# ARM_Example register map
Vendor: ARM Ltd.; Series: ARMCM3; File version: 1.2
ARM 32-bit Cortex-M3 Microcontroller based device, CPU clock up to 80MHz, etc.
CPU: CM3 r1p0, little endian, MPU, no FPU, 3 interrupt priority bits
Registers are 32-bit, read-write, reset 0x0 unless marked. A register's access mark holds for its fields unless they carry their own. Offsets are from the block's base; lines under a group give offsets from that group; [hi:lo] are bit positions; {n}, {i} and the like mark numbered series; 'fields as' and 'values as' point back to an identical list; <NAME> marks a mode.

## Memory map
0x40010000 TIMER0 size 0x100 — 32 Timer / Counter, counting up or down from different sources
0x40010100 TIMER1 size 0x100
0x40010200 TIMER2 size 0x100
0x40020000 TEST1
0x40030000 TEST2

## Interrupts
0 TIMER0
4 TIMER1
6 TIMER2

## TEST1
Base 0x40020000; register names take the prefix TEST1_
Same registers: TEST2 0x40030000 (register names take the prefix TEST1_; register names take the suffix _TEST2)
0x00 BASE1 reset 0x8001 — Timer Control Register
  [0] EN — Enable
    0=Disable (Timer is disabled and does not operate); 1=Enable (Timer is enabled and can operate)
? DIMNOINDEX{i} (i=0..3; step 0x4) reset 0x12345678 (reset mask 0x87654321)
0x04 DERIVED1 reset 0x8001 — Derived register
  fields as BASE1
0x08 DERIVED2 reset 0x8001 — Derived register
  fields as BASE1
0x10 INHERITED reset 0x12345678 (reset mask 0x87654321)
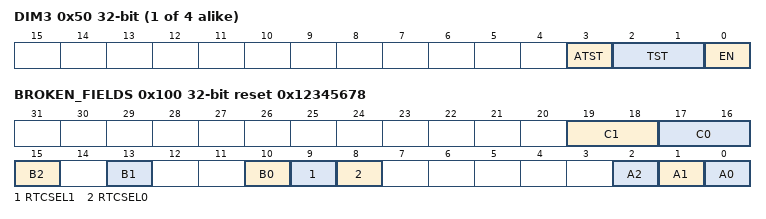
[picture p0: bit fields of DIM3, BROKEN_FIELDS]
{0x44+4i} DIM{i} (i=3..6) — test register
  [3] ATST — Another Test
  [2:1] TST — Test
  [0] EN — Enable
    values as BASE1.EN
0x100 BROKEN_FIELDS reset 0x12345678 (reset mask 0x87654321) — A register with broken field, e.g A1, A2, A3 which are supposed to only one field, name A
  [19:18] C1
  [17:16] C0
  [15] B2
  [13] B1
  [10] B0
  [9] RTCSEL1 — RTC clock source selection
  [8] RTCSEL0 — RTC clock source selection
  [2] A2
  [1] A1
  [0] A0

## Licence text in the file
ARM Limited (ARM) is supplying this software for use with Cortex-M processor based microcontroller, but can be equally used for other suitable processor architectures. This file can be freely distributed. Modifications to this file shall be clearly marked. . THIS SOFTWARE IS PROVIDED "AS IS". NO WARRANTIES, WHETHER EXPRESS, IMPLIED. OR STATUTORY, INCLUDING, BUT NOT LIMITED TO, IMPLIED WARRANTIES OF. MERCHANTABILITY AND FITNESS FOR A PARTICULAR PURPOSE APPLY TO THIS SOFTWARE. ARM SHALL NOT, IN ANY CIRCUMSTANCES, BE LIABLE FOR SPECIAL, INCIDENTAL, OR. CONSEQUENTIAL DAMAGES, FOR ANY REASON WHATSOEVER.

## Notices in the file
Copyright (C) 2012-2014 ARM Limited. All rights reserved.
Copyright (C) 2018 BayLibre
Purpose: System Viewer Description (SVD) Example (Schema Version 1.1)
This is a description of a none-existent and incomplete device
for demonstration purposes only.
Redistribution and use in source and binary forms, with or without
modification, are permitted provided that the following conditions are met:
- Redistributions of source code must retain the above copyright
notice, this list of conditions and the following disclaimer.
- Redistributions in binary form must reproduce the above copyright
notice, this list of conditions and the following disclaimer in the
documentation and/or other materials provided with the distribution.
- Neither the name of ARM nor the names of its contributors may be used
to endorse or promote products derived from this software without
specific prior written permission.
THIS SOFTWARE IS PROVIDED BY THE COPYRIGHT HOLDERS AND CONTRIBUTORS "AS IS"
AND ANY EXPRESS OR IMPLIED WARRANTIES, INCLUDING, BUT NOT LIMITED TO, THE
ARE DISCLAIMED. IN NO EVENT SHALL COPYRIGHT HOLDERS AND CONTRIBUTORS BE
LIABLE FOR ANY DIRECT, INDIRECT, INCIDENTAL, SPECIAL, EXEMPLARY, OR
CONSEQUENTIAL DAMAGES (INCLUDING, BUT NOT LIMITED TO, PROCUREMENT OF
SUBSTITUTE GOODS OR SERVICES; LOSS OF USE, DATA, OR PROFITS; OR BUSINESS
INTERRUPTION) HOWEVER CAUSED AND ON ANY THEORY OF LIABILITY, WHETHER IN
CONTRACT, STRICT LIABILITY, OR TORT (INCLUDING NEGLIGENCE OR OTHERWISE)
ARISING IN ANY WAY OUT OF THE USE OF THIS SOFTWARE, EVEN IF ADVISED OF THE
POSSIBILITY OF SUCH DAMAGE.
